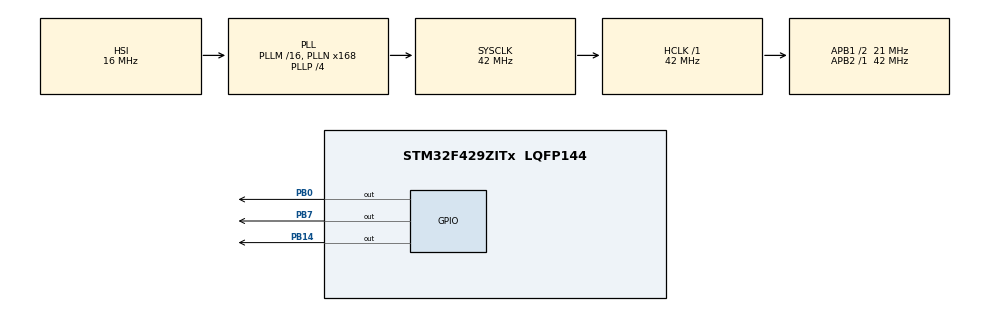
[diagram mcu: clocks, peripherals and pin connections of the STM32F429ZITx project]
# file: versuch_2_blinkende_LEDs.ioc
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Mcu.Family=STM32F4
Mcu.Name=STM32F429ZITx
Mcu.Package=LQFP144
NVIC.PriorityGroup=NVIC_PRIORITYGROUP_4
NVIC.TIM4_IRQn=true\:0\:0\:false\:false\:true\:true\:true\:true
PB0.Signal=GPIO_Output
PB14.Signal=GPIO_Output
PB7.Signal=GPIO_Output
ProjectManager.HeapSize=0x200
ProjectManager.StackSize=0x400
ProjectManager.TargetToolchain=STM32CubeIDE
RCC.48MHZClocksFreq_Value=42000000
RCC.AHBFreq_Value=42000000
RCC.APB1CLKDivider=RCC_HCLK_DIV2
RCC.APB1Freq_Value=21000000
RCC.APB1TimFreq_Value=42000000
RCC.APB2Freq_Value=42000000
RCC.APB2TimFreq_Value=42000000
RCC.CortexFreq_Value=42000000
RCC.HCLKFreq_Value=42000000
RCC.HSE_VALUE=25000000
RCC.HSI_VALUE=16000000
RCC.LSE_VALUE=32768
RCC.PLLN=168
RCC.PLLP=RCC_PLLP_DIV4
RCC.SYSCLKFreq_VALUE=42000000
RCC.SYSCLKSource=RCC_SYSCLKSOURCE_PLLCLK
RCC.VCOOutputFreq_Value=168000000
TIM4.Period=999
TIM4.Prescaler=41999
VP_TIM4_VS_ClockSourceINT.Mode=Internal
board=custom

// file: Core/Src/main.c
/* USER CODE BEGIN Header */
/**
  ******************************************************************************
  * @file           : main.c
  * @brief          : Main program body
  ******************************************************************************
  * @attention
  *
  * Copyright (c) 2023 STMicroelectronics.
  * All rights reserved.
  *
  * This software is licensed under terms that can be found in the LICENSE file
  * in the root directory of this software component.
  * If no LICENSE file comes with this software, it is provided AS-IS.
  *
  ******************************************************************************
  */
/* USER CODE END Header */
#include "main.h"

TIM_HandleTypeDef htim4;

void SystemClock_Config(void);
static void MX_GPIO_Init(void);
static void MX_TIM4_Init(void);

/* USER CODE BEGIN 0 */

uint8_t currentLED = 0;

/* USER CODE END 0 */

int main(void)
{

  /* MCU Configuration--------------------------------------------------------*/

  /* Reset of all peripherals, Initializes the Flash interface and the Systick. */
  HAL_Init();

  /* Configure the system clock */
  SystemClock_Config();

  /* Initialize all configured peripherals */
  MX_GPIO_Init();
  MX_TIM4_Init();
  /* USER CODE BEGIN 2 */
  HAL_TIM_Base_Start_IT(&htim4);
  /* USER CODE END 2 */

  /* Infinite loop */
  while (1)
  {

  }
}

void SystemClock_Config(void)
{
  RCC_OscInitTypeDef RCC_OscInitStruct = {0};
  RCC_ClkInitTypeDef RCC_ClkInitStruct = {0};

  /** Configure the main internal regulator output voltage
  */
  __HAL_RCC_PWR_CLK_ENABLE();
  __HAL_PWR_VOLTAGESCALING_CONFIG(PWR_REGULATOR_VOLTAGE_SCALE3);

  /** Initializes the RCC Oscillators according to the specified parameters
  * in the RCC_OscInitTypeDef structure.
  */
  RCC_OscInitStruct.OscillatorType = RCC_OSCILLATORTYPE_HSI;
  RCC_OscInitStruct.HSIState = RCC_HSI_ON;
  RCC_OscInitStruct.HSICalibrationValue = RCC_HSICALIBRATION_DEFAULT;
  RCC_OscInitStruct.PLL.PLLState = RCC_PLL_ON;
  RCC_OscInitStruct.PLL.PLLSource = RCC_PLLSOURCE_HSI;
  RCC_OscInitStruct.PLL.PLLM = 16;
  RCC_OscInitStruct.PLL.PLLN = 168;
  RCC_OscInitStruct.PLL.PLLP = RCC_PLLP_DIV4;
  RCC_OscInitStruct.PLL.PLLQ = 4;
  if (HAL_RCC_OscConfig(&RCC_OscInitStruct) != HAL_OK)
  {
    Error_Handler();
  }

  /** Initializes the CPU, AHB and APB buses clocks
  */
  RCC_ClkInitStruct.ClockType = RCC_CLOCKTYPE_HCLK|RCC_CLOCKTYPE_SYSCLK
                              |RCC_CLOCKTYPE_PCLK1|RCC_CLOCKTYPE_PCLK2;
  RCC_ClkInitStruct.SYSCLKSource = RCC_SYSCLKSOURCE_PLLCLK;
  RCC_ClkInitStruct.AHBCLKDivider = RCC_SYSCLK_DIV1;
  RCC_ClkInitStruct.APB1CLKDivider = RCC_HCLK_DIV2;
  RCC_ClkInitStruct.APB2CLKDivider = RCC_HCLK_DIV1;

  if (HAL_RCC_ClockConfig(&RCC_ClkInitStruct, FLASH_LATENCY_1) != HAL_OK)
  {
    Error_Handler();
  }
}

static void MX_TIM4_Init(void)
{

  TIM_ClockConfigTypeDef sClockSourceConfig = {0};
  TIM_MasterConfigTypeDef sMasterConfig = {0};

  htim4.Instance = TIM4;
  htim4.Init.Prescaler = 41999;
  htim4.Init.CounterMode = TIM_COUNTERMODE_UP;
  htim4.Init.Period = 999;
  htim4.Init.ClockDivision = TIM_CLOCKDIVISION_DIV1;
  htim4.Init.AutoReloadPreload = TIM_AUTORELOAD_PRELOAD_DISABLE;
  if (HAL_TIM_Base_Init(&htim4) != HAL_OK)
  {
    Error_Handler();
  }
  sClockSourceConfig.ClockSource = TIM_CLOCKSOURCE_INTERNAL;
  if (HAL_TIM_ConfigClockSource(&htim4, &sClockSourceConfig) != HAL_OK)
  {
    Error_Handler();
  }
  sMasterConfig.MasterOutputTrigger = TIM_TRGO_RESET;
  sMasterConfig.MasterSlaveMode = TIM_MASTERSLAVEMODE_DISABLE;
  if (HAL_TIMEx_MasterConfigSynchronization(&htim4, &sMasterConfig) != HAL_OK)
  {
    Error_Handler();
  }

}

static void MX_GPIO_Init(void)
{
  GPIO_InitTypeDef GPIO_InitStruct = {0};

  /* GPIO Ports Clock Enable */
  __HAL_RCC_GPIOB_CLK_ENABLE();

  /*Configure GPIO pin Output Level */
  HAL_GPIO_WritePin(GPIOB, GPIO_PIN_0|GPIO_PIN_14|GPIO_PIN_7, GPIO_PIN_RESET);

  /*Configure GPIO pins : PB0 PB14 PB7 */
  GPIO_InitStruct.Pin = GPIO_PIN_0|GPIO_PIN_14|GPIO_PIN_7;
  GPIO_InitStruct.Mode = GPIO_MODE_OUTPUT_PP;
  GPIO_InitStruct.Pull = GPIO_NOPULL;
  GPIO_InitStruct.Speed = GPIO_SPEED_FREQ_LOW;
  HAL_GPIO_Init(GPIOB, &GPIO_InitStruct);

}

/* USER CODE BEGIN 4 */
void HAL_TIM_PeriodElapsedCallback(TIM_HandleTypeDef *htim)
{
    if(htim->Instance == TIM4)  // Check if it's indeed Timer 4 interrupt
    {
        // Assuming the LEDs are connected to GPIOB with pins GPIO_PIN_0, GPIO_PIN_14, and GPIO_PIN_7
        switch(currentLED)
        {
            case 0:
                HAL_GPIO_TogglePin(GPIOB, GPIO_PIN_0);   // Toggle LED1
                break;
            case 1:
                HAL_GPIO_TogglePin(GPIOB, GPIO_PIN_7);  // Toggle LED2
                break;
            case 2:
                HAL_GPIO_TogglePin(GPIOB, GPIO_PIN_14);   // Toggle LED3
                break;
        }

        // Update currentLED state
        if(currentLED == 2)
            currentLED = 1;
        else if(currentLED == 1 && HAL_GPIO_ReadPin(GPIOB, GPIO_PIN_7) == GPIO_PIN_SET)  // If LED2 is ON, go to LED1 next
            currentLED = 0;
        else
            currentLED++;
    }
}
/* USER CODE END 4 */

void Error_Handler(void)
{
  __disable_irq();
  while (1)
  {
  }
}
